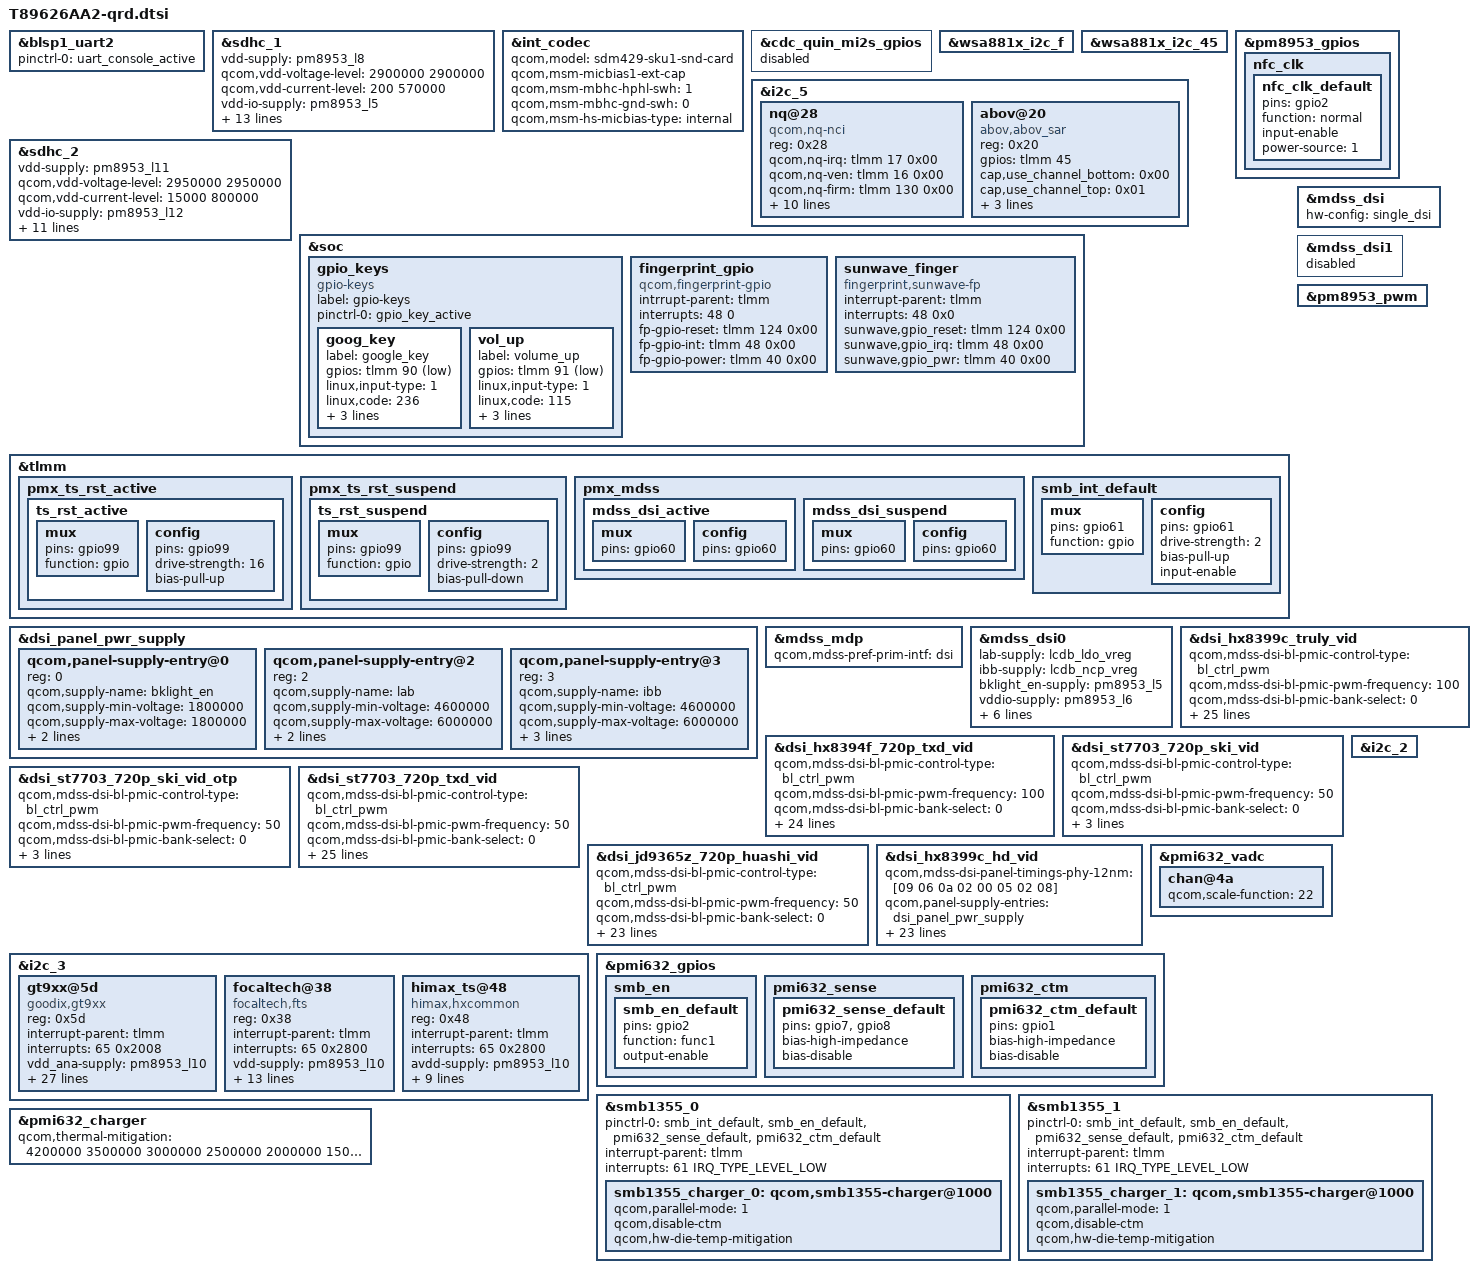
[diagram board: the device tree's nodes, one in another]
/*
 * Copyright (c) 2018-2019, The Linux Foundation. All rights reserved.
 *
 * This program is free software; you can redistribute it and/or modify
 * it under the terms of the GNU General Public License version 2 and
 * only version 2 as published by the Free Software Foundation.
 *
 * This program is distributed in the hope that it will be useful,
 * but WITHOUT ANY WARRANTY; without even the implied warranty of
 * MERCHANTABILITY or FITNESS FOR A PARTICULAR PURPOSE.  See the
 * GNU General Public License for more details.
 */

#include "msm8937-mdss-panels.dtsi"
#include "sdm429-camera-sensor-qrd.dtsi"

&blsp1_uart2 {
	status = "ok";
	pinctrl-names = "default";
	pinctrl-0 = <&uart_console_active>;
};

&sdhc_1 {
	/* device core power supply */
	vdd-supply = <&pm8953_l8>;
	qcom,vdd-voltage-level = <2900000 2900000>;
	qcom,vdd-current-level = <200 570000>;

	/* device communication power supply */
	vdd-io-supply = <&pm8953_l5>;
	qcom,vdd-io-always-on;
	qcom,vdd-io-lpm-sup;
	qcom,vdd-io-voltage-level = <1800000 1800000>;
	qcom,vdd-io-current-level = <200 325000>;

	pinctrl-names = "active", "sleep";
	pinctrl-0 = <&sdc1_clk_on &sdc1_cmd_on &sdc1_data_on &sdc1_rclk_on>;
	pinctrl-1 = <&sdc1_clk_off &sdc1_cmd_off &sdc1_data_off &sdc1_rclk_off>;

	qcom,clk-rates = <400000 20000000 25000000 50000000 100000000 192000000
								384000000>;
	qcom,nonremovable;
	qcom,bus-speed-mode = "HS400_1p8v", "HS200_1p8v", "DDR_1p8v";

	status = "ok";
};

&int_codec {
	status = "okay";
	qcom,model = "sdm429-sku1-snd-card";
	qcom,msm-micbias1-ext-cap;
	qcom,msm-mbhc-hphl-swh = <1>;
	qcom,msm-mbhc-gnd-swh = <0>;
	qcom,msm-hs-micbias-type = "internal";
	/delete-property/ qcom,quin-mi2s-gpios;
};

&cdc_quin_mi2s_gpios {
	status = "disabled";
};

&wsa881x_i2c_f {
	status = "okay";
};

&wsa881x_i2c_45 {
	status = "okay";
};

&pm8953_gpios {
	nfc_clk {
		nfc_clk_default: nfc_clk_default {
			pins = "gpio2";
			function = "normal";
			input-enable;
			power-source = <1>;
		};
	};
};

&i2c_5 { /* BLSP2 QUP1 (NFC) */
	#address-cells = <1>;
	#size-cells = <0>;

	status = "ok";
	nq@28 {
		compatible = "qcom,nq-nci";
		reg = <0x28>;
		qcom,nq-irq = <&tlmm 17 0x00>;
		qcom,nq-ven = <&tlmm 16 0x00>;
		qcom,nq-firm = <&tlmm 130 0x00>;
		qcom,nq-clkreq = <&pm8953_gpios 2 0x00>;
		qcom,nq-esepwr = <&tlmm 93 0x00>;
		interrupt-parent = <&tlmm>;
		qcom,clk-src = "BBCLK2";
		interrupts = <17 0>;
		interrupt-names = "nfc_irq";
		pinctrl-names = "nfc_active", "nfc_suspend";
		pinctrl-0 = <&nfc_int_active &nfc_disable_active
						&nfc_clk_default>;
		pinctrl-1 = <&nfc_int_suspend &nfc_disable_suspend>;
		clocks = <&clock_gcc clk_bb_clk2_pin>;
		clock-names = "ref_clk";
	};

	 abov@20 {
		 compatible = "abov,abov_sar";
		 reg = <0x20>;
		 gpios = <&tlmm 45 0>;
		 cap,use_channel_bottom = <0x00>;
		 cap,use_channel_top = <0x01>;
		 vdd-supply = <&pm8953_l10>;
		 vcc_i2c-supply = <&pm8953_l6>;
		 label = "AbovCapSense";
	 };
};

&sdhc_2 {
	/* device core power supply */
	vdd-supply = <&pm8953_l11>;
	qcom,vdd-voltage-level = <2950000 2950000>;
	qcom,vdd-current-level = <15000 800000>;

	/* device communication power supply */
	vdd-io-supply = <&pm8953_l12>;
	qcom,vdd-io-voltage-level = <1800000 2950000>;
	qcom,vdd-io-current-level = <200 22000>;

	pinctrl-names = "active", "sleep";
	pinctrl-0 = <&sdc2_clk_on &sdc2_cmd_on &sdc2_data_on &sdc2_cd_on>;
	pinctrl-1 = <&sdc2_clk_off &sdc2_cmd_off &sdc2_data_off>;

	cd-gpios = <&tlmm 67 0x0>;

	qcom,clk-rates = <400000 20000000 25000000 50000000 100000000
								200000000>;
	qcom,bus-speed-mode = "SDR12", "SDR25", "SDR50", "DDR50", "SDR104";

	status = "ok";
};

&soc {
	gpio_keys: gpio_keys {
		compatible = "gpio-keys";
		label = "gpio-keys";
		pinctrl-names = "default";
		pinctrl-0 = <&gpio_key_active>;
		goog_key: goog_key {
			label = "google_key";
			gpios = <&tlmm 90 0x1>;
			linux,input-type = <1>;
			linux,code = <236>;
			debounce-interval = <15>;
			gpio-key,wakeup;
			linux,can-disable;
		};
		vol_up: vol_up {
			label = "volume_up";
			gpios = <&tlmm 91 0x1>;
			linux,input-type = <1>;
			linux,code = <115>;
			debounce-interval = <15>;
			linux,can-disable;
			gpio-key,wakeup;
		};
	};
/*
	fpc1020 {
		compatible = "fpc,fpc1020";
		interrupt-parent = <&tlmm>;
		interrupts = <48 0>;
		fpc,gpio_rst = <&tlmm 124 0x0>;
		fpc,gpio_irq = <&tlmm 48 0>;
		vcc_spi-supply = <&pm8953_l5>;
		vdd_io-supply  = <&pm8953_l5>;
		vdd_ana-supply = <&pm8953_l5>;
		fpc,enable-on-boot;
		pinctrl-names = "fpc1020_reset_reset",
				"fpc1020_reset_active",
				"fpc1020_irq_active";
		pinctrl-0 = <&fpc_reset_low>;
		pinctrl-1 = <&fpc_reset_high>;
		pinctrl-2 = <&fpc_int_low>;
	};
*/
		fingerprint_gpio{
                  compatible = "qcom,fingerprint-gpio";
                  intrrupt-parent = <&tlmm>;
		  interrupts = <48 0>;
                  fp-gpio-reset = <&tlmm 124 0x00>;
                  fp-gpio-int   = <&tlmm 48 0x00>;
                  fp-gpio-power = <&tlmm 40 0x00>;
                  status = "okay";
                           };

	sunwave_finger {
                compatible = "fingerprint,sunwave-fp";
                interrupt-parent = <&tlmm>;
                interrupts = <48 0x0>;
                sunwave,gpio_reset = <&tlmm 124 0x00>;
                sunwave,gpio_irq   = <&tlmm 48 0x00>;
                sunwave,gpio_pwr   = <&tlmm 40 0x00>;
                status = "okay";
	};
};

&tlmm {
	pmx_ts_rst_active {
		ts_rst_active: ts_rst_active {
			mux {
				pins = "gpio99";
				function = "gpio";
			};

			config {
				pins = "gpio99";
				drive-strength = <16>;
				bias-pull-up;
			};
		};
	};

	pmx_ts_rst_suspend {
		ts_rst_suspend: ts_rst_suspend {
			mux {
				pins = "gpio99";
				function = "gpio";
			};

			config {
				pins = "gpio99";
				drive-strength = <2>;
				bias-pull-down;
			};
		};
	};
};

&soc {
/*	hbtp {
		compatible = "qcom,hbtp-input";
		pinctrl-names = "pmx_ts_active", "pmx_ts_suspend";
		pinctrl-0 = <&ts_rst_active>;
		pinctrl-1 = <&ts_rst_suspend>;
		vcc_ana-supply = <&pm8953_l10>;
		vcc_dig-supply = <&pm8953_l5>;
		qcom,afe-load = <20000>;
		qcom,afe-vtg-min = <3000000>;
		qcom,afe-vtg-max = <3000000>;
		qcom,dig-load = <40000>;
		qcom,dig-vtg-min = <1800000>;
		qcom,dig-vtg-max = <1800000>;
		qcom,fb-resume-delay-us = <1000>;
		qcom,afe-force-power-on;
		qcom,afe-power-on-delay-us = <6>;
		qcom,afe-power-off-delay-us = <6>;
	};
*/
};

&tlmm {
	pmx_mdss {
		mdss_dsi_active: mdss_dsi_active {
			mux {
				pins = "gpio60";
			};
			config {
				pins = "gpio60";
			};
		};
		mdss_dsi_suspend: mdss_dsi_suspend {
			mux {
				pins = "gpio60";
			};
			config {
				pins = "gpio60";
			};
		};
	};
};

&dsi_panel_pwr_supply {
	qcom,panel-supply-entry@0 {
		reg = <0>;
		qcom,supply-name = "bklight_en";
		qcom,supply-min-voltage = <1800000>;
		qcom,supply-max-voltage = <1800000>;
		qcom,supply-enable-load = <100000>;
		qcom,supply-disable-load = <100>;
	};

	qcom,panel-supply-entry@2 {
		reg = <2>;
		qcom,supply-name = "lab";
		qcom,supply-min-voltage = <4600000>;
		qcom,supply-max-voltage = <6000000>;
		qcom,supply-enable-load = <100000>;
		qcom,supply-disable-load = <100>;
	};

	qcom,panel-supply-entry@3 {
		reg = <3>;
		qcom,supply-name = "ibb";
		qcom,supply-min-voltage = <4600000>;
		qcom,supply-max-voltage = <6000000>;
		qcom,supply-enable-load = <100000>;
		qcom,supply-disable-load = <100>;
		qcom,supply-post-on-sleep = <10>;
	};
};

&mdss_dsi {
	hw-config = "single_dsi";
};

&mdss_mdp {
	qcom,mdss-pref-prim-intf = "dsi";
};

&mdss_dsi0 {
	lab-supply = <&lcdb_ldo_vreg>;
	ibb-supply = <&lcdb_ncp_vreg>;
	bklight_en-supply = <&pm8953_l5>;
	vddio-supply = <&pm8953_l6>;

	qcom,dsi-pref-prim-pan = <&dsi_st7703_720p_ski_vid>;
	/delete-property/ qcom,platform-bklight-en-gpio;
	pinctrl-names = "mdss_default", "mdss_sleep";
	pinctrl-0 = <&mdss_dsi_active &mdss_te_active>;
	pinctrl-1 = <&mdss_dsi_suspend &mdss_te_suspend>;
	qcom,platform-te-gpio = <&tlmm 24 0>;
	qcom,platform-reset-gpio = <&tlmm 60 0>;
};

&mdss_dsi1 {
	status = "disabled";
};

&pm8953_pwm {
	status = "ok";
};

&dsi_hx8399c_truly_vid {
	qcom,mdss-dsi-bl-pmic-control-type = "bl_ctrl_pwm";
	qcom,mdss-dsi-bl-pmic-pwm-frequency = <100>;
	qcom,mdss-dsi-bl-pmic-bank-select = <0>;
	qcom,mdss-dsi-pwm-gpio = <&pm8953_gpios 8 0>;
	qcom,panel-supply-entries = <&dsi_panel_pwr_supply>;
	/delete-property/ qcom,mdss-dsi-panel-timings;
	qcom,mdss-dsi-panel-timings-phy-12nm = [18 0a 10 06 03 08 06 0e];
	qcom,mdss-dsi-t-clk-post = <0x02>;
	qcom,mdss-dsi-t-clk-pre = <0x2d>;
	qcom,esd-check-enabled;
	qcom,mdss-dsi-panel-status-check-mode = "reg_read";
	qcom,mdss-dsi-panel-status-command = [06 01 00 01 00 00 01 0a];
	qcom,mdss-dsi-panel-status-command-state = "dsi_lp_mode";
	qcom,mdss-dsi-panel-status-value = <0x9d 0x9d 0x9d 0x9d>;
	qcom,mdss-dsi-panel-on-check-value = <0x9d 0x9d 0x9d 0x9d>;
	qcom,mdss-dsi-panel-status-read-length = <4>;
	qcom,mdss-dsi-panel-max-error-count = <3>;
	qcom,mdss-dsi-min-refresh-rate = <48>;
	qcom,mdss-dsi-max-refresh-rate = <60>;
	qcom,mdss-dsi-pan-enable-dynamic-fps;
	qcom,mdss-dsi-pan-fps-update =
		"dfps_immediate_porch_mode_vfp";
};
&dsi_hx8394f_720p_txd_vid {
	qcom,mdss-dsi-bl-pmic-control-type = "bl_ctrl_pwm";
	qcom,mdss-dsi-bl-pmic-pwm-frequency = <100>;
	qcom,mdss-dsi-bl-pmic-bank-select = <0>;
	qcom,mdss-dsi-pwm-gpio = <&pm8953_gpios 8 0>;
	qcom,panel-supply-entries = <&dsi_panel_pwr_supply>;
	/delete-property/ qcom,mdss-dsi-panel-timings;
	qcom,mdss-dsi-panel-timings-phy-12nm = [18 0a 10 06 03 08 06 0e];
	qcom,mdss-dsi-t-clk-post = <0x02>;
	qcom,mdss-dsi-t-clk-pre = <0x2d>;
	qcom,mdss-dsi-panel-status-check-mode = "reg_read";
	qcom,mdss-dsi-panel-status-command = [06 01 00 01 00 00 01 0a];
	qcom,mdss-dsi-panel-status-command-state = "dsi_lp_mode";
	qcom,mdss-dsi-panel-status-value = <0x9d 0x9d 0x9d 0x9d>;
	qcom,mdss-dsi-panel-on-check-value = <0x9d 0x9d 0x9d 0x9d>;
	qcom,mdss-dsi-panel-status-read-length = <4>;
	qcom,mdss-dsi-panel-max-error-count = <3>;
	qcom,mdss-dsi-min-refresh-rate = <48>;
	qcom,mdss-dsi-max-refresh-rate = <60>;
	qcom,mdss-dsi-pan-enable-dynamic-fps;
	qcom,mdss-dsi-pan-fps-update =
		"dfps_immediate_porch_mode_vfp";
};

&dsi_st7703_720p_ski_vid {
	qcom,mdss-dsi-bl-pmic-control-type = "bl_ctrl_pwm";
	qcom,mdss-dsi-bl-pmic-pwm-frequency = <50>;  
	qcom,mdss-dsi-bl-pmic-bank-select = <0>;
	qcom,mdss-dsi-pwm-gpio = <&pm8953_gpios 8 0>;
	qcom,panel-supply-entries = <&dsi_panel_pwr_supply>;
};

&dsi_st7703_720p_ski_vid_otp {
	qcom,mdss-dsi-bl-pmic-control-type = "bl_ctrl_pwm";
	qcom,mdss-dsi-bl-pmic-pwm-frequency = <50>;
	qcom,mdss-dsi-bl-pmic-bank-select = <0>;
	qcom,mdss-dsi-pwm-gpio = <&pm8953_gpios 8 0>;
	qcom,panel-supply-entries = <&dsi_panel_pwr_supply>;
};

&dsi_st7703_720p_txd_vid {
	qcom,mdss-dsi-bl-pmic-control-type = "bl_ctrl_pwm";
	qcom,mdss-dsi-bl-pmic-pwm-frequency = <50>;
	qcom,mdss-dsi-bl-pmic-bank-select = <0>;
	qcom,mdss-dsi-pwm-gpio = <&pm8953_gpios 8 0>;
	qcom,panel-supply-entries = <&dsi_panel_pwr_supply>;
	/delete-property/ qcom,mdss-dsi-panel-timings;
	qcom,mdss-dsi-panel-timings-phy-12nm = [0e 00 08 06 0c 04 04 0a];
	qcom,mdss-dsi-t-clk-post = <0x02>;
	qcom,mdss-dsi-t-clk-pre = <0x2d>;
	qcom,esd-check-enabled;
	qcom,mdss-dsi-panel-status-check-mode = "reg_read";
	qcom,mdss-dsi-panel-status-command = [06 01 00 01 00 00 01 09
					      06 01 00 01 00 00 01 af
					      06 01 00 01 00 00 01 68];
	qcom,mdss-dsi-panel-status-command-state = "dsi_lp_mode";
	qcom,mdss-dsi-panel-status-value = <0x80 0x73 0x04 0xfd 0xc0>;
	qcom,mdss-dsi-panel-on-check-value = <0x80 0x73 0x04 0xfd 0xc0>;
	qcom,mdss-dsi-panel-status-valid-params = <3 1 1>;
	qcom,mdss-dsi-panel-status-read-length = <3 1 1>;
	qcom,mdss-dsi-panel-max-error-count = <3>;
	qcom,mdss-dsi-min-refresh-rate = <48>;
	qcom,mdss-dsi-max-refresh-rate = <60>;
	//qcom,mdss-dsi-pan-enable-dynamic-fps;
	qcom,mdss-dsi-pan-fps-update =
		"dfps_immediate_porch_mode_vfp";
};

&dsi_jd9365z_720p_huashi_vid {
	qcom,mdss-dsi-bl-pmic-control-type = "bl_ctrl_pwm";
	qcom,mdss-dsi-bl-pmic-pwm-frequency = <50>;
	qcom,mdss-dsi-bl-pmic-bank-select = <0>;
	qcom,mdss-dsi-pwm-gpio = <&pm8953_gpios 8 0>;
	qcom,panel-supply-entries = <&dsi_panel_pwr_supply>;
	/delete-property/ qcom,mdss-dsi-panel-timings;
	qcom,mdss-dsi-panel-timings-phy-12nm = [0e 08 0c 04 00 06 04 0a];
	qcom,mdss-dsi-t-clk-post = <0x02>;
	qcom,mdss-dsi-t-clk-pre = <0x2d>;
	qcom,esd-check-enabled;
	qcom,mdss-dsi-panel-status-check-mode = "reg_read";
	qcom,mdss-dsi-panel-status-command = [06 01 00 01 00 00 01 0a];
	qcom,mdss-dsi-panel-status-command-state = "dsi_lp_mode";
	qcom,mdss-dsi-panel-status-value = <0x1c>;
	qcom,mdss-dsi-panel-on-check-value = <0x1c>;
	qcom,mdss-dsi-panel-status-read-length = <1>;
	qcom,mdss-dsi-panel-max-error-count = <3>;
	qcom,mdss-dsi-min-refresh-rate = <48>;
	qcom,mdss-dsi-max-refresh-rate = <60>;
	qcom,mdss-dsi-pan-enable-dynamic-fps;
	qcom,mdss-dsi-pan-fps-update =
		"dfps_immediate_porch_mode_vfp";
};

&dsi_hx8399c_hd_vid {
	/delete-property/ qcom,mdss-dsi-panel-timings;
	qcom,mdss-dsi-panel-timings-phy-12nm = [09 06 0a 02 00 05 02 08];
	qcom,panel-supply-entries = <&dsi_panel_pwr_supply>;
	qcom,mdss-dsi-bl-pmic-control-type = "bl_ctrl_pwm";
	qcom,mdss-dsi-bl-pmic-pwm-frequency = <100>;
	qcom,mdss-dsi-bl-pmic-bank-select = <0>;
	qcom,mdss-dsi-pwm-gpio = <&pm8953_gpios 8 0>;
	qcom,esd-check-enabled;
	qcom,mdss-dsi-panel-status-check-mode = "reg_read";
	qcom,mdss-dsi-panel-status-command = [06 01 00 01 00 00 01 0a];
	qcom,mdss-dsi-panel-status-command-state = "dsi_lp_mode";
	qcom,mdss-dsi-panel-status-value = <0x9d 0x9d 0x9d 0x9d>;
	qcom,mdss-dsi-panel-on-check-value = <0x9d 0x9d 0x9d 0x9d>;
	qcom,mdss-dsi-panel-status-read-length = <4>;
	qcom,mdss-dsi-panel-max-error-count = <3>;
	qcom,mdss-dsi-min-refresh-rate = <48>;
	qcom,mdss-dsi-max-refresh-rate = <60>;
	qcom,mdss-dsi-pan-enable-dynamic-fps;
	qcom,mdss-dsi-pan-fps-update =
		"dfps_immediate_porch_mode_vfp";
};

&i2c_2 {
#address-cells = <1>;
#size-cells = <0>;

#include "smb1355.dtsi"
};

&i2c_3 {
	status = "ok";

gt9xx@5d {
	compatible = "goodix,gt9xx";
	reg = <0x5d>; 
	interrupt-parent = <&tlmm>;
	interrupts = <65 0x2008>;
	vdd_ana-supply = <&pm8953_l10>;
	vcc_i2c-supply = <&pm8953_l6>;
#if 0
	pinctrl-names = "pmx_ts_active","pmx_ts_suspend","pmx_ts_release";
	pinctrl-0 = <&ts_int_active &ts_reset_active>;
	pinctrl-1 = <&ts_int_suspend &ts_reset_suspend>;
	pinctrl-2 = <&ts_release>;
#endif
	pinctrl-names = "default", "int-output-low","int-output-high", "int-input";
	pinctrl-0 = <&ts_int_default>;
	pinctrl-1 = <&ts_int_output_low>;
	pinctrl-2 = <&ts_int_output_high>;
	pinctrl-3 = <&ts_int_input>;


	reset-gpios = <&tlmm 64 0x00>;
	irq-gpios = <&tlmm 65 0x2008>;
	irq-flags = <2>;
	touchscreen-max-id = <5>;
	touchscreen-size-x = <720>;
	touchscreen-size-y = <1520>;
	touchscreen-max-w = <1024>;
	touchscreen-max-p = <1024>;
	touchscreen-key-map = <172>, <158>; /*KEY_HOMEPAGE=172, KEY_BACK=158，KEY_MENU=139*/
	goodix,slide-wakeup = <0>;
	goodix,type-a-report = <0>;
	goodix,driver-send-cfg = <1>;
	goodix,resume-in-workqueue = <0>;
	goodix,int-sync = <1>;
	goodix,swap-x2y = <0>;
	goodix,esd-protect = <1>;
        goodix,auto-update-cfg = <1>;
        goodix,auto-update = <1>;
        goodix,power-off-sleep = <0>;
	goodix,pen-suppress-finger = <0>;
	goodix,cfg-group0 = [
	52 D0 02 F0 05 05 7D 08 22 AF 28 0F 50 32 03 03 00 00 00 00 08 01 08 28 26 2A 28 87 27 EE 46 48 D0 05 FF E4 00 03 32 11 00 00 00 00 00 00 40 00 00 00 42 32 5A 94 D0 52 07 00 00 04 A2 35 00 94 3B 00 84 43 00 78 4B 00 6D 55 00 6D 00 00 00 00 00 00 00 00 00 00 00 00 00 00 00 00 00 00 FF 67 00 00 0A 23 00 00 00 00 46 01 46 00 00 00 00 32 00 01 02 03 04 05 06 07 08 09 0A 0B 0C 0D 0E 0F 10 11 12 13 14 15 16 17 18 19 1A 1B FF FF 00 02 04 05 06 08 0A 1E 1F 20 22 24 29 2A FF FF FF 00 00 00 00 00 00 00 00 00 00 00 00 00 00 00 00 00 00 00 00 00 00 00 00 00 00 00 00 00 00 00 1E 3C 00 00 00 00 00 00 00 00 00 00 00 00 00 00 64 50 00 00 A0 00 80 0C 00 00 00 00 00 44 44 58 9A 4C 00 00 E6 01
	];
};
#if 1
focaltech@38{
	compatible = "focaltech,fts";
	reg = <0x38>;
	interrupt-parent = <&tlmm>;
	interrupts = <65 0x2800>;
	vdd-supply = <&pm8953_l10>;
	vcc_i2c-supply = <&pm8953_l6>;
	focaltech,reset-gpio = <&tlmm 64 0x00>;
	focaltech,irq-gpio = <&tlmm 65 0x2008>;
	focaltech,max-touch-number = <5>;
	focaltech,display-coords =  <0 0 720 1520>;
	pinctrl-names = "pmx_ts_active","pmx_ts_suspend","pmx_ts_release";
	pinctrl-0 = <&ts_int_active &ts_reset_active>;
	pinctrl-1 = <&ts_int_suspend &ts_reset_suspend>;
	pinctrl-2 = <&ts_release>;
	focaltech,have-key;
	focaltech,key-number = <3>;
	focaltech,keys = <158 139 172>;
	focaltech,key-y-coord = <2000>;
	focaltech,key-x-coords = <200 600 800>;
};


himax_ts@48{
        compatible = "himax,hxcommon";
        reg = <0x48>;
        interrupt-parent = <&tlmm>;
        interrupts = <65 0x2800>;
        avdd-supply = <&pm8953_l10>;
        vdd-supply = <&pm8953_l6>;
        himax,rst-gpio = <&tlmm 64 0x00>;
        himax,irq-gpio = <&tlmm 65 0x2008>;
        himax,panel-coords = <0 720 0 1520>;
        himax,display-coords =  <0 720 0 1520>;
        pinctrl-names = "pmx_ts_active","pmx_ts_suspend","pmx_ts_release";
        pinctrl-0 = <&ts_int_active &ts_reset_active>;
        pinctrl-1 = <&ts_int_suspend &ts_reset_suspend>;
        pinctrl-2 = <&ts_release>;
        report_type = <1>;
};
#endif
};
&pmi632_vadc {
	chan@4a {
		qcom,scale-function = <22>;
	};
};

&pmi632_gpios {
	smb_en {
		smb_en_default: smb_en_default {
			pins = "gpio2";
			function = "func1";
			output-enable;
		};
	};

	pmi632_sense {
		/* GPIO 7 and 8 are external-sense pins for PMI632 */
		pmi632_sense_default: pmi632_sense_default {
			pins = "gpio7", "gpio8";
			bias-high-impedance;	/* disable the GPIO */
			bias-disable;		/* no-pull */
		};
	};

	pmi632_ctm {
		/* Disable GPIO1 for h/w base mitigation */
		pmi632_ctm_default: pmi632_ctm_default {
			pins = "gpio1";
			bias-high-impedance;	/* disable the GPIO */
			bias-disable;		/* no-pull */
		};
	};
};

&tlmm {
	smb_int_default: smb_int_default {
		mux {
			pins = "gpio61";
			function = "gpio";
		};
		config {
			pins = "gpio61";
			drive-strength = <2>;
			bias-pull-up;
			input-enable;
		};
	};
};

&smb1355_0 {
	pinctrl-names = "default";
	pinctrl-0 = <&smb_int_default
		&smb_en_default &pmi632_sense_default &pmi632_ctm_default>;
	interrupt-parent = <&tlmm>;
	interrupts = <61 IRQ_TYPE_LEVEL_LOW>;
	smb1355_charger_0: qcom,smb1355-charger@1000 {
		status ="ok";
		/delete-property/ io-channels;
		/delete-property/ io-channels-names;
		qcom,parallel-mode = <1>;
		qcom,disable-ctm;
		qcom,hw-die-temp-mitigation;
	};
};

&smb1355_1 {
	pinctrl-names = "default";
	pinctrl-0 = <&smb_int_default
		&smb_en_default &pmi632_sense_default &pmi632_ctm_default>;
	interrupt-parent = <&tlmm>;
	interrupts = <61 IRQ_TYPE_LEVEL_LOW>;
	smb1355_charger_1: qcom,smb1355-charger@1000 {
		status ="ok";
		/delete-property/ io-channels;
		/delete-property/ io-channels-names;
		qcom,parallel-mode = <1>;
		qcom,disable-ctm;
		qcom,hw-die-temp-mitigation;
	};
};

&pmi632_charger {
	qcom,thermal-mitigation = <4200000 3500000 3000000 2500000
				2000000 1500000 1000000 500000>;
};
